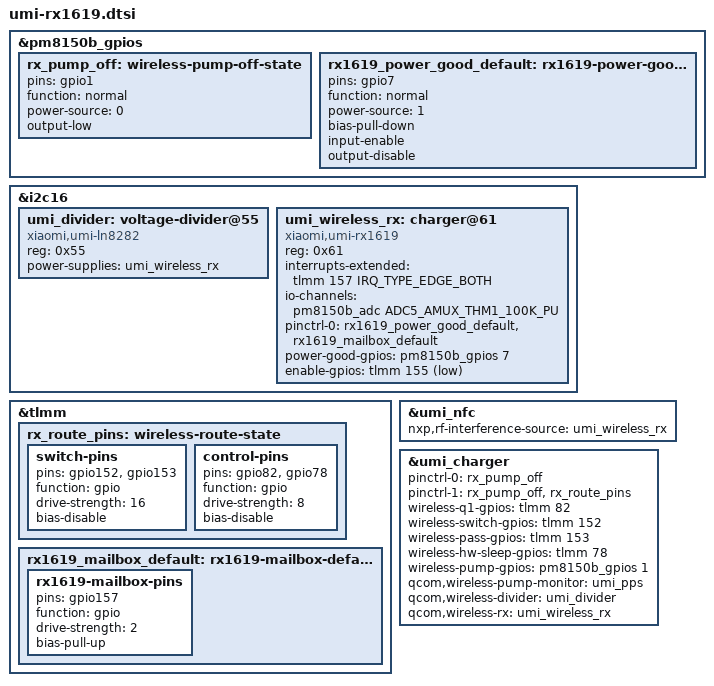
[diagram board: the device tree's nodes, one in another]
// SPDX-License-Identifier: GPL-2.0-only
/* Umi LineageOS active DT at 71b13e62: QUP16, 0x61, PM8150B GPIO7 and TLMM 155/157.
 * PM8150B GPIO1 is the downstream wireless charge-pump request, not a wired BQ control.
 */

&pm8150b_gpios {
	rx_pump_off: wireless-pump-off-state {
		pins = "gpio1";
		function = "normal";
		power-source = <0>;
		output-low;
	};
	rx1619_power_good_default: rx1619-power-good-default-state {
		pins = "gpio7";
		function = "normal";
		power-source = <1>;
		bias-pull-down;
		input-enable;
		output-disable;
	};
};

&i2c16 {
	status = "okay";

	umi_divider: voltage-divider@55 {
		compatible = "xiaomi,umi-ln8282";
		reg = <0x55>;
		power-supplies = <&umi_wireless_rx>;
	};

	umi_wireless_rx: charger@61 {
		compatible = "xiaomi,umi-rx1619";
		reg = <0x61>;
		interrupts-extended = <&tlmm 157 IRQ_TYPE_EDGE_BOTH>;
		io-channels = <&pm8150b_adc ADC5_AMUX_THM1_100K_PU>;
		io-channel-names = "ambient";
		pinctrl-names = "default";
		pinctrl-0 = <&rx1619_power_good_default &rx1619_mailbox_default>;
		power-good-gpios = <&pm8150b_gpios 7 GPIO_ACTIVE_HIGH>;
		enable-gpios = <&tlmm 155 GPIO_ACTIVE_LOW>;
	};
};

&tlmm {
	rx_route_pins: wireless-route-state {
		switch-pins {
			pins = "gpio152", "gpio153";
			function = "gpio";
			drive-strength = <16>;
			bias-disable;
		};
		control-pins {
			pins = "gpio82", "gpio78";
			function = "gpio";
			drive-strength = <8>;
			bias-disable;
		};
	};
	rx1619_mailbox_default: rx1619-mailbox-default-state {
		rx1619-mailbox-pins {
			pins = "gpio157";
			function = "gpio";
			drive-strength = <2>;
			bias-pull-up;
		};
	};
};

&umi_nfc {
	nxp,rf-interference-source = <&umi_wireless_rx>;
};

&umi_charger {
	/* Keep GPIO1 deasserted by default; EPP also claims the routing pins. */
	pinctrl-names = "default", "rx-pump-off";
	pinctrl-0 = <&rx_pump_off>;
	pinctrl-1 = <&rx_pump_off &rx_route_pins>;
	wireless-q1-gpios = <&tlmm 82 GPIO_ACTIVE_HIGH>;
	wireless-switch-gpios = <&tlmm 152 GPIO_ACTIVE_HIGH>;
	wireless-pass-gpios = <&tlmm 153 GPIO_ACTIVE_HIGH>;
	wireless-hw-sleep-gpios = <&tlmm 78 GPIO_ACTIVE_HIGH>;
	wireless-pump-gpios = <&pm8150b_gpios 1 GPIO_ACTIVE_HIGH>;
	qcom,wireless-pump-monitor = <&umi_pps>;
	qcom,wireless-divider = <&umi_divider>;
	qcom,wireless-rx = <&umi_wireless_rx>;
};
